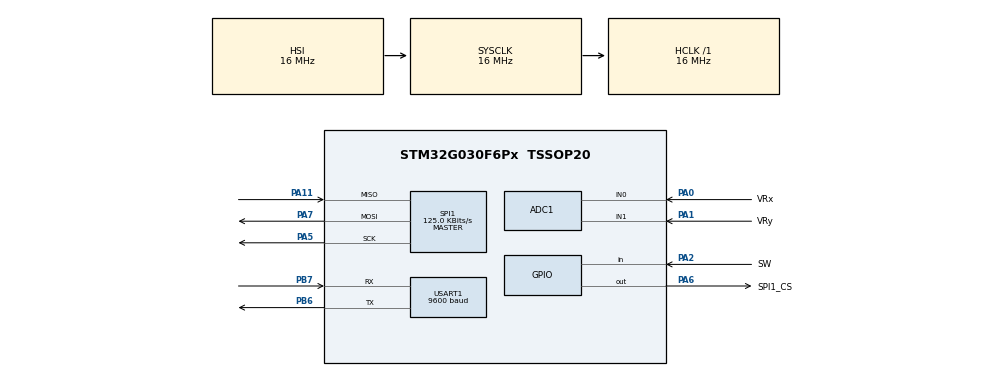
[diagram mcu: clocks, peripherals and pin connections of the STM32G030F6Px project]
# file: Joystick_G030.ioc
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ADC1.Channel-2\#ChannelRegularConversion=ADC_CHANNEL_1
ADC1.ContinuousConvMode=DISABLE
ADC1.NbrOfConversion=1
ADC1.NbrOfConversionFlag=1
ADC1.Rank-2\#ChannelRegularConversion=1
ADC1.SamplingTime-2\#ChannelRegularConversion=ADC_SAMPLINGTIME_COMMON_1
ADC1.SelectedChannel=ADC_CHANNEL_0|ADC_CHANNEL_1
ADC1.master=1
Mcu.Family=STM32G0
Mcu.Name=STM32G030F6Px
Mcu.Package=TSSOP20
PA0.GPIO_Label=VRx
PA0.Mode=IN0
PA0.Signal=ADC1_IN0
PA1.GPIO_Label=VRy
PA1.Mode=IN1
PA1.Signal=ADC1_IN1
PA11\ [PA9].Mode=Full_Duplex_Master
PA11\ [PA9].Signal=SPI1_MISO
PA13.Mode=Serial_Wire
PA13.Signal=SYS_SWDIO
PA14-BOOT0.Mode=Serial_Wire
PA14-BOOT0.Signal=SYS_SWCLK
PA14-BOOT0__PA15.StandardMode=true
PA2.GPIO_Label=SW
PA2.GPIO_PuPd=GPIO_PULLUP
PA2.Signal=GPIO_Input
PA5.Mode=Full_Duplex_Master
PA5.Signal=SPI1_SCK
PA6.GPIO_Label=SPI1_CS
PA6.Signal=GPIO_Output
PA7.Mode=Full_Duplex_Master
PA7.Signal=SPI1_MOSI
PB0__PB1__PB2__PA8.StandardMode=true
PB3__PB4__PB5__PB6.StandardMode=true
PB6.Mode=Asynchronous
PB6.Signal=USART1_TX
PB7.Mode=Asynchronous
PB7.Signal=USART1_RX
PB7__PB8.StandardMode=true
PC14-OSC32_IN\ (PC14)__PB9.StandardMode=true
ProjectManager.HeapSize=0x200
ProjectManager.StackSize=0x400
ProjectManager.TargetToolchain=STM32CubeIDE
RCC.ADCFreq_Value=16000000
RCC.AHBFreq_Value=16000000
RCC.CortexFreq_Value=16000000
RCC.EXTERNAL_CLOCK_VALUE=12288000
RCC.HCLKFreq_Value=16000000
RCC.HSE_VALUE=8000000
RCC.HSI_VALUE=16000000
RCC.LSE_VALUE=32768
RCC.SYSCLKFreq_VALUE=16000000
RCC.VCOOutputFreq_Value=128000000
SPI1.BaudRatePrescaler=SPI_BAUDRATEPRESCALER_128
SPI1.CalculateBaudRate=125.0 KBits/s
SPI1.DataSize=SPI_DATASIZE_8BIT
SPI1.Direction=SPI_DIRECTION_2LINES
SPI1.Mode=SPI_MODE_MASTER
SPI1.VirtualType=VM_MASTER
USART1.BaudRate=9600
USART1.VirtualMode-Asynchronous=VM_ASYNC
board=custom

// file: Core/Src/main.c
/* USER CODE BEGIN Header */
/**
 ******************************************************************************
 * @file           : main.c
 * @brief          : Main program body
 ******************************************************************************
 * @attention
 *
 * Copyright (c) 2025 STMicroelectronics.
 * All rights reserved.
 *
 * This software is licensed under terms that can be found in the LICENSE file
 * in the root directory of this software component.
 * If no LICENSE file comes with this software, it is provided AS-IS.
 *
 ******************************************************************************
 */
/* USER CODE END Header */
#include "main.h"

/* USER CODE BEGIN Includes */
#include "max7219.h"
#include "game_logic.h"

/* USER CODE END Includes */

ADC_HandleTypeDef hadc1;

SPI_HandleTypeDef hspi1;

UART_HandleTypeDef huart1;

void SystemClock_Config(void);
static void MX_GPIO_Init(void);
static void MX_ADC1_Init(void);
static void MX_USART1_UART_Init(void);
static void MX_SPI1_Init(void);

int main(void) {

	/* MCU Configuration--------------------------------------------------------*/

	/* Reset of all peripherals, Initializes the Flash interface and the Systick. */
	HAL_Init();

	/* Configure the system clock */
	SystemClock_Config();

	/* Initialize all configured peripherals */
	MX_GPIO_Init();
	MX_ADC1_Init();
	MX_USART1_UART_Init();
	MX_SPI1_Init();
	/* USER CODE BEGIN 2 */
	MAX7219_Init(&hspi1);

	/* USER CODE END 2 */

	/* Infinite loop */
	/* USER CODE BEGIN WHILE */

	while (1) {
		setup_game(&hspi1, &hadc1);

		/* USER CODE END WHILE */

	}
}

void SystemClock_Config(void) {
	RCC_OscInitTypeDef RCC_OscInitStruct = { 0 };
	RCC_ClkInitTypeDef RCC_ClkInitStruct = { 0 };

	/** Configure the main internal regulator output voltage
	 */
	HAL_PWREx_ControlVoltageScaling(PWR_REGULATOR_VOLTAGE_SCALE1);

	/** Initializes the RCC Oscillators according to the specified parameters
	 * in the RCC_OscInitTypeDef structure.
	 */
	RCC_OscInitStruct.OscillatorType = RCC_OSCILLATORTYPE_HSI;
	RCC_OscInitStruct.HSIState = RCC_HSI_ON;
	RCC_OscInitStruct.HSIDiv = RCC_HSI_DIV1;
	RCC_OscInitStruct.HSICalibrationValue = RCC_HSICALIBRATION_DEFAULT;
	RCC_OscInitStruct.PLL.PLLState = RCC_PLL_NONE;
	if (HAL_RCC_OscConfig(&RCC_OscInitStruct) != HAL_OK) {
		Error_Handler();
	}

	/** Initializes the CPU, AHB and APB buses clocks
	 */
	RCC_ClkInitStruct.ClockType = RCC_CLOCKTYPE_HCLK | RCC_CLOCKTYPE_SYSCLK
			| RCC_CLOCKTYPE_PCLK1;
	RCC_ClkInitStruct.SYSCLKSource = RCC_SYSCLKSOURCE_HSI;
	RCC_ClkInitStruct.AHBCLKDivider = RCC_SYSCLK_DIV1;
	RCC_ClkInitStruct.APB1CLKDivider = RCC_HCLK_DIV1;

	if (HAL_RCC_ClockConfig(&RCC_ClkInitStruct, FLASH_LATENCY_0) != HAL_OK) {
		Error_Handler();
	}
}

static void MX_ADC1_Init(void) {

	ADC_ChannelConfTypeDef sConfig = { 0 };

	/** Configure the global features of the ADC (Clock, Resolution, Data Alignment and number of conversion)
	 */
	hadc1.Instance = ADC1;
	hadc1.Init.ClockPrescaler = ADC_CLOCK_SYNC_PCLK_DIV2;
	hadc1.Init.Resolution = ADC_RESOLUTION_12B;
	hadc1.Init.DataAlign = ADC_DATAALIGN_RIGHT;
	hadc1.Init.ScanConvMode = ADC_SCAN_DISABLE;
	hadc1.Init.EOCSelection = ADC_EOC_SINGLE_CONV;
	hadc1.Init.LowPowerAutoWait = DISABLE;
	hadc1.Init.LowPowerAutoPowerOff = DISABLE;
	hadc1.Init.ContinuousConvMode = DISABLE;
	hadc1.Init.NbrOfConversion = 1;
	hadc1.Init.DiscontinuousConvMode = DISABLE;
	hadc1.Init.ExternalTrigConv = ADC_SOFTWARE_START;
	hadc1.Init.ExternalTrigConvEdge = ADC_EXTERNALTRIGCONVEDGE_NONE;
	hadc1.Init.DMAContinuousRequests = DISABLE;
	hadc1.Init.Overrun = ADC_OVR_DATA_PRESERVED;
	hadc1.Init.SamplingTimeCommon1 = ADC_SAMPLETIME_1CYCLE_5;
	hadc1.Init.SamplingTimeCommon2 = ADC_SAMPLETIME_1CYCLE_5;
	hadc1.Init.OversamplingMode = DISABLE;
	hadc1.Init.TriggerFrequencyMode = ADC_TRIGGER_FREQ_HIGH;
	if (HAL_ADC_Init(&hadc1) != HAL_OK) {
		Error_Handler();
	}

	/** Configure Regular Channel
	 */
	sConfig.Channel = ADC_CHANNEL_1;
	sConfig.Rank = ADC_REGULAR_RANK_1;
	sConfig.SamplingTime = ADC_SAMPLINGTIME_COMMON_1;
	if (HAL_ADC_ConfigChannel(&hadc1, &sConfig) != HAL_OK) {
		Error_Handler();
	}

}

static void MX_SPI1_Init(void) {

	/* SPI1 parameter configuration*/
	hspi1.Instance = SPI1;
	hspi1.Init.Mode = SPI_MODE_MASTER;
	hspi1.Init.Direction = SPI_DIRECTION_2LINES;
	hspi1.Init.DataSize = SPI_DATASIZE_8BIT;
	hspi1.Init.CLKPolarity = SPI_POLARITY_LOW;
	hspi1.Init.CLKPhase = SPI_PHASE_1EDGE;
	hspi1.Init.NSS = SPI_NSS_SOFT;
	hspi1.Init.BaudRatePrescaler = SPI_BAUDRATEPRESCALER_128;
	hspi1.Init.FirstBit = SPI_FIRSTBIT_MSB;
	hspi1.Init.TIMode = SPI_TIMODE_DISABLE;
	hspi1.Init.CRCCalculation = SPI_CRCCALCULATION_DISABLE;
	hspi1.Init.CRCPolynomial = 7;
	hspi1.Init.CRCLength = SPI_CRC_LENGTH_DATASIZE;
	hspi1.Init.NSSPMode = SPI_NSS_PULSE_ENABLE;
	if (HAL_SPI_Init(&hspi1) != HAL_OK) {
		Error_Handler();
	}

}

static void MX_USART1_UART_Init(void) {

	huart1.Instance = USART1;
	huart1.Init.BaudRate = 9600;
	huart1.Init.WordLength = UART_WORDLENGTH_8B;
	huart1.Init.StopBits = UART_STOPBITS_1;
	huart1.Init.Parity = UART_PARITY_NONE;
	huart1.Init.Mode = UART_MODE_TX_RX;
	huart1.Init.HwFlowCtl = UART_HWCONTROL_NONE;
	huart1.Init.OverSampling = UART_OVERSAMPLING_16;
	huart1.Init.OneBitSampling = UART_ONE_BIT_SAMPLE_DISABLE;
	huart1.Init.ClockPrescaler = UART_PRESCALER_DIV1;
	huart1.AdvancedInit.AdvFeatureInit = UART_ADVFEATURE_NO_INIT;
	if (HAL_UART_Init(&huart1) != HAL_OK) {
		Error_Handler();
	}
	if (HAL_UARTEx_SetTxFifoThreshold(&huart1, UART_TXFIFO_THRESHOLD_1_8)
			!= HAL_OK) {
		Error_Handler();
	}
	if (HAL_UARTEx_SetRxFifoThreshold(&huart1, UART_RXFIFO_THRESHOLD_1_8)
			!= HAL_OK) {
		Error_Handler();
	}
	if (HAL_UARTEx_DisableFifoMode(&huart1) != HAL_OK) {
		Error_Handler();
	}

}

static void MX_GPIO_Init(void) {
	GPIO_InitTypeDef GPIO_InitStruct = { 0 };

	/* GPIO Ports Clock Enable */
	__HAL_RCC_GPIOB_CLK_ENABLE();
	__HAL_RCC_GPIOA_CLK_ENABLE();

	/*Configure GPIO pin Output Level */
	HAL_GPIO_WritePin(SPI1_CS_GPIO_Port, SPI1_CS_Pin, GPIO_PIN_RESET);

	/*Configure GPIO pin : SW_Pin */
	GPIO_InitStruct.Pin = SW_Pin;
	GPIO_InitStruct.Mode = GPIO_MODE_INPUT;
	GPIO_InitStruct.Pull = GPIO_PULLUP;
	HAL_GPIO_Init(SW_GPIO_Port, &GPIO_InitStruct);

	/*Configure GPIO pin : SPI1_CS_Pin */
	GPIO_InitStruct.Pin = SPI1_CS_Pin;
	GPIO_InitStruct.Mode = GPIO_MODE_OUTPUT_PP;
	GPIO_InitStruct.Pull = GPIO_NOPULL;
	GPIO_InitStruct.Speed = GPIO_SPEED_FREQ_LOW;
	HAL_GPIO_Init(SPI1_CS_GPIO_Port, &GPIO_InitStruct);

}

void Error_Handler(void) {
	__disable_irq();
	while (1) {
	}
}
